AUTOSAR XML (schema 4-0-3)
package /ComponentTypes
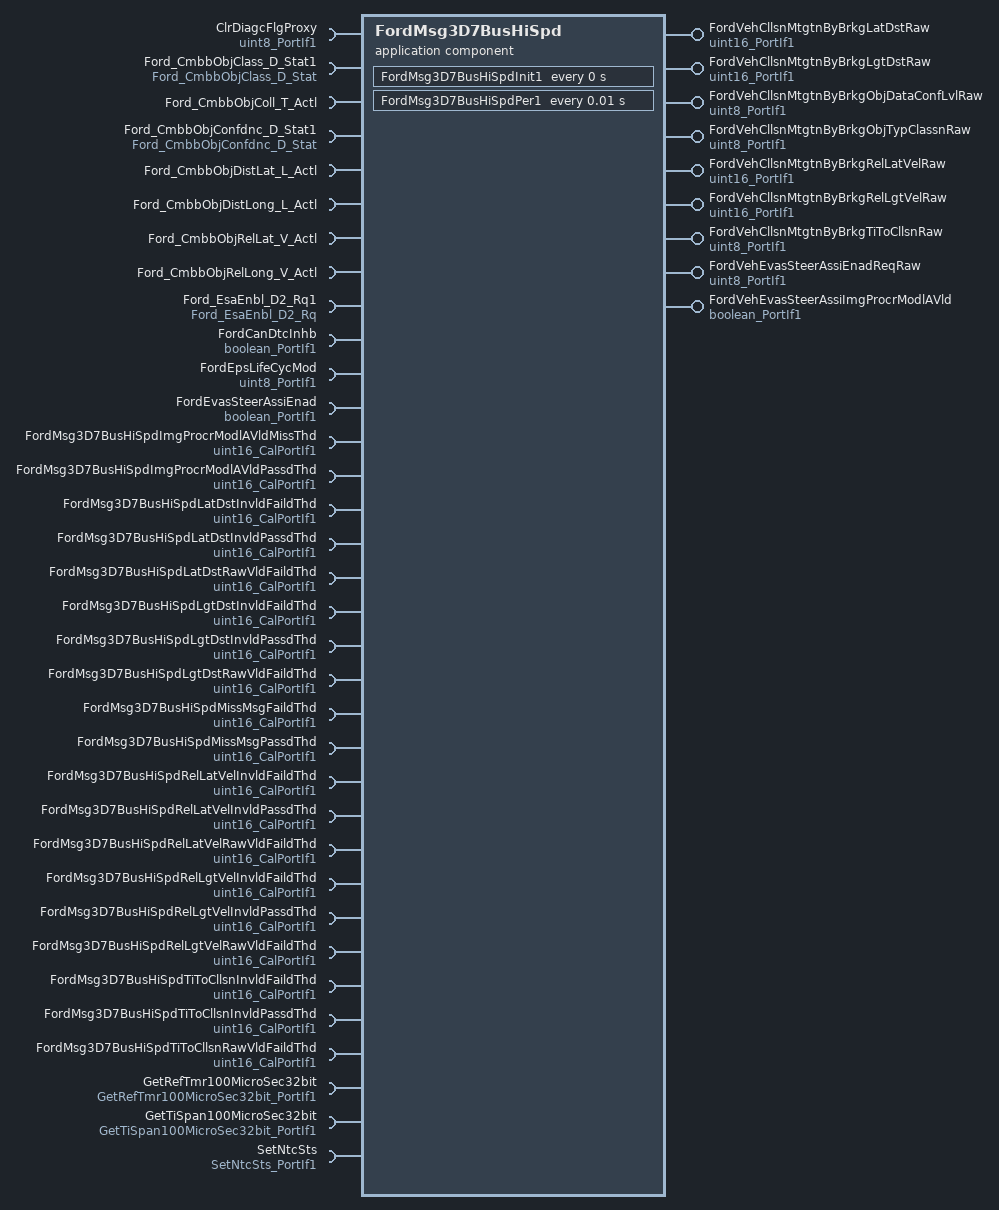
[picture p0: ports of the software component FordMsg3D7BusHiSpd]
  application sw component type FordMsg3D7BusHiSpd
    9 x provide port:
      FordVehCllsnMtgtnByBrkgLatDstRaw: nonqueued-sender-com-spec{data-element=Val, init-value=510}, provided-interface=uint16_PortIf1
      FordVehCllsnMtgtnByBrkgLgtDstRaw: nonqueued-sender-com-spec{data-element=Val, init-value=1022}, provided-interface=uint16_PortIf1
      FordVehCllsnMtgtnByBrkgObjDataConfLvlRaw: nonqueued-sender-com-spec{data-element=Val, init-value=0}, provided-interface=uint8_PortIf1
      FordVehCllsnMtgtnByBrkgObjTypClassnRaw: nonqueued-sender-com-spec{data-element=Val, init-value=0}, provided-interface=uint8_PortIf1
      FordVehCllsnMtgtnByBrkgRelLatVelRaw: nonqueued-sender-com-spec{data-element=Val, init-value=510}, provided-interface=uint16_PortIf1
      FordVehCllsnMtgtnByBrkgRelLgtVelRaw: nonqueued-sender-com-spec{data-element=Val, init-value=1022}, provided-interface=uint16_PortIf1
      FordVehCllsnMtgtnByBrkgTiToCllsnRaw: nonqueued-sender-com-spec{data-element=Val, init-value=126}, provided-interface=uint8_PortIf1
      FordVehEvasSteerAssiEnadReqRaw: nonqueued-sender-com-spec{data-element=Val, init-value=0}, provided-interface=uint8_PortIf1
      FordVehEvasSteerAssiImgProcrModlAVld: nonqueued-sender-com-spec{data-element=Logl, init-value=0}, provided-interface=boolean_PortIf1
    34 x require port:
      ClrDiagcFlgProxy: nonqueued-receiver-com-spec{data-element=Val, filter=data-filter-type=ALWAYS, init-value=0}, required-interface=uint8_PortIf1
      Ford_CmbbObjClass_D_Stat1: nonqueued-receiver-com-spec{data-element=Ford_CmbbObjClass_D_Stat, filter=data-filter-type=ALWAYS, init-value=0}, required-interface=Ford_CmbbObjClass_D_Stat
      Ford_CmbbObjColl_T_Actl: nonqueued-receiver-com-spec{data-element=Ford_CmbbObjColl_T_Actl, filter=data-filter-type=ALWAYS, init-value=126}, required-interface=Ford_CmbbObjColl_T_Actl
      Ford_CmbbObjConfdnc_D_Stat1: nonqueued-receiver-com-spec{data-element=Ford_CmbbObjConfdnc_D_Stat, filter=data-filter-type=ALWAYS, init-value=0}, required-interface=Ford_CmbbObjConfdnc_D_Stat
      Ford_CmbbObjDistLat_L_Actl: nonqueued-receiver-com-spec{data-element=Ford_CmbbObjDistLat_L_Actl, filter=data-filter-type=ALWAYS, init-value=510}, required-interface=Ford_CmbbObjDistLat_L_Actl
      Ford_CmbbObjDistLong_L_Actl: nonqueued-receiver-com-spec{data-element=Ford_CmbbObjDistLong_L_Actl, filter=data-filter-type=ALWAYS, init-value=1022}, required-interface=Ford_CmbbObjDistLong_L_Actl
      Ford_CmbbObjRelLat_V_Actl: nonqueued-receiver-com-spec{data-element=Ford_CmbbObjRelLat_V_Actl, filter=data-filter-type=ALWAYS, init-value=510}, required-interface=Ford_CmbbObjRelLat_V_Actl
      Ford_CmbbObjRelLong_V_Actl: nonqueued-receiver-com-spec{data-element=Ford_CmbbObjRelLong_V_Actl, filter=data-filter-type=ALWAYS, init-value=1022}, required-interface=Ford_CmbbObjRelLong_V_Actl
      Ford_EsaEnbl_D2_Rq1: nonqueued-receiver-com-spec{data-element=Ford_EsaEnbl_D2_Rq, filter=data-filter-type=ALWAYS, init-value=0}, required-interface=Ford_EsaEnbl_D2_Rq
      FordCanDtcInhb: nonqueued-receiver-com-spec{data-element=Logl, filter=data-filter-type=ALWAYS, init-value=1}, required-interface=boolean_PortIf1
      FordEpsLifeCycMod: nonqueued-receiver-com-spec{data-element=Val, filter=data-filter-type=ALWAYS, init-value=0}, required-interface=uint8_PortIf1
      FordEvasSteerAssiEnad: nonqueued-receiver-com-spec{data-element=Logl, filter=data-filter-type=ALWAYS, init-value=0}, required-interface=boolean_PortIf1
      FordMsg3D7BusHiSpdImgProcrModlAVldMissThd: parameter-require-com-spec{init-value=500, parameter=Val}, required-interface=uint16_CalPortIf1
      FordMsg3D7BusHiSpdImgProcrModlAVldPassdThd: parameter-require-com-spec{init-value=5000, parameter=Val}, required-interface=uint16_CalPortIf1
      FordMsg3D7BusHiSpdLatDstInvldFaildThd: parameter-require-com-spec{init-value=0, parameter=Val}, required-interface=uint16_CalPortIf1
      FordMsg3D7BusHiSpdLatDstInvldPassdThd: parameter-require-com-spec{init-value=0, parameter=Val}, required-interface=uint16_CalPortIf1
      FordMsg3D7BusHiSpdLatDstRawVldFaildThd: parameter-require-com-spec{init-value=0, parameter=Val}, required-interface=uint16_CalPortIf1
      FordMsg3D7BusHiSpdLgtDstInvldFaildThd: parameter-require-com-spec{init-value=0, parameter=Val}, required-interface=uint16_CalPortIf1
      FordMsg3D7BusHiSpdLgtDstInvldPassdThd: parameter-require-com-spec{init-value=0, parameter=Val}, required-interface=uint16_CalPortIf1
      FordMsg3D7BusHiSpdLgtDstRawVldFaildThd: parameter-require-com-spec{init-value=0, parameter=Val}, required-interface=uint16_CalPortIf1
      FordMsg3D7BusHiSpdMissMsgFaildThd: parameter-require-com-spec{init-value=500, parameter=Val}, required-interface=uint16_CalPortIf1
      FordMsg3D7BusHiSpdMissMsgPassdThd: parameter-require-com-spec{init-value=0, parameter=Val}, required-interface=uint16_CalPortIf1
      FordMsg3D7BusHiSpdRelLatVelInvldFaildThd: parameter-require-com-spec{init-value=0, parameter=Val}, required-interface=uint16_CalPortIf1
      FordMsg3D7BusHiSpdRelLatVelInvldPassdThd: parameter-require-com-spec{init-value=0, parameter=Val}, required-interface=uint16_CalPortIf1
      FordMsg3D7BusHiSpdRelLatVelRawVldFaildThd: parameter-require-com-spec{init-value=0, parameter=Val}, required-interface=uint16_CalPortIf1
      FordMsg3D7BusHiSpdRelLgtVelInvldFaildThd: parameter-require-com-spec{init-value=0, parameter=Val}, required-interface=uint16_CalPortIf1
      FordMsg3D7BusHiSpdRelLgtVelInvldPassdThd: parameter-require-com-spec{init-value=0, parameter=Val}, required-interface=uint16_CalPortIf1
      FordMsg3D7BusHiSpdRelLgtVelRawVldFaildThd: parameter-require-com-spec{init-value=0, parameter=Val}, required-interface=uint16_CalPortIf1
      FordMsg3D7BusHiSpdTiToCllsnInvldFaildThd: parameter-require-com-spec{init-value=0, parameter=Val}, required-interface=uint16_CalPortIf1
      FordMsg3D7BusHiSpdTiToCllsnInvldPassdThd: parameter-require-com-spec{init-value=0, parameter=Val}, required-interface=uint16_CalPortIf1
      FordMsg3D7BusHiSpdTiToCllsnRawVldFaildThd: parameter-require-com-spec{init-value=0, parameter=Val}, required-interface=uint16_CalPortIf1
      GetRefTmr100MicroSec32bit: client-com-spec=Oper, required-interface=GetRefTmr100MicroSec32bit_PortIf1
      GetTiSpan100MicroSec32bit: client-com-spec=Oper, required-interface=GetTiSpan100MicroSec32bit_PortIf1
      SetNtcSts: client-com-spec=Oper, required-interface=SetNtcSts_PortIf1
    behavior FordMsg3D7BusHiSpd_InternalBehavior
      ar-typed-per-instance-memorys:
        31 x data, all with sw-calibration-access=READ-ONLY:
          ClrDiagcFlgProxyPrev: type=uint8
          EvasSteerAssiImgProcrModlAVldPassdRefTi: type=uint32
          FirstTranVldFlg: type=boolean
          FordVehCllsnMtgtnByBrkgLatDstInvldFaildRefTi: type=uint32
          FordVehCllsnMtgtnByBrkgLatDstInvldPassdRefTi: type=uint32
          FordVehCllsnMtgtnByBrkgLatDstRawPrev: type=uint16
          FordVehCllsnMtgtnByBrkgLgtDstInvldFaildRefTi: type=uint32
          FordVehCllsnMtgtnByBrkgLgtDstInvldPassdRefTi: type=uint32
          FordVehCllsnMtgtnByBrkgLgtDstRawPrev: type=uint16
          FordVehCllsnMtgtnByBrkgObjDataConfLvlRawPrev: type=uint8
          FordVehCllsnMtgtnByBrkgObjTypClassnRawPrev: type=uint8
          FordVehCllsnMtgtnByBrkgRelLatVelInvldFaildRefTi: type=uint32
          FordVehCllsnMtgtnByBrkgRelLatVelInvldPassdRefTi: type=uint32
          FordVehCllsnMtgtnByBrkgRelLatVelRawPrev: type=uint16
          FordVehCllsnMtgtnByBrkgRelLgtVelInvldFaildRefTi: type=uint32
          FordVehCllsnMtgtnByBrkgRelLgtVelInvldPassdRefTi: type=uint32
          FordVehCllsnMtgtnByBrkgRelLgtVelRawPrev: type=uint16
          FordVehCllsnMtgtnByBrkgTiToCllsnInvldFaildRefTi: type=uint32
          FordVehCllsnMtgtnByBrkgTiToCllsnInvldPassdRefTi: type=uint32
          FordVehCllsnMtgtnByBrkgTiToCllsnRawPrev: type=uint8
          FordVehEvasSteerAssiEnadReqRawPrev: type=uint8
          FordVehEvasSteerAssiImgProcrModlAVldPrev: type=boolean
          FordVehMsg3D7Miss: type=boolean
          ImgProcrModlAVldMissRefTi: type=uint32
          LatDstRawVldFaildRefTi: type=uint32
          LgtDstRawVldFaildRefTi: type=uint32
          MissMsgFaildRefTi: type=uint32
          MissMsgPassdRefTi: type=uint32
          RelLatVelRawVldFaildRefTi: type=uint32
          RelLgtVelRawVldFaildRefTi: type=uint32
          TiToCllsnRawVldFaildRefTi: type=uint32
      timing event FordMsg3D7BusHiSpd_InitEvent: start-on-event=FordMsg3D7BusHiSpdInit1, period=0
      timing event TMT_FordMsg3D7BusHiSpdPer1: start-on-event=FordMsg3D7BusHiSpdPer1, period=0.01
      port-api-options:
        enable-take-address=false, indirect-api=false, port=ClrDiagcFlgProxy
        enable-take-address=false, indirect-api=false, port=Ford_CmbbObjClass_D_Stat1
        enable-take-address=false, indirect-api=false, port=Ford_CmbbObjColl_T_Actl
        enable-take-address=false, indirect-api=false, port=Ford_CmbbObjConfdnc_D_Stat1
        enable-take-address=false, indirect-api=false, port=Ford_CmbbObjDistLat_L_Actl
        enable-take-address=false, indirect-api=false, port=Ford_CmbbObjDistLong_L_Actl
        enable-take-address=false, indirect-api=false, port=Ford_CmbbObjRelLat_V_Actl
        enable-take-address=false, indirect-api=false, port=Ford_CmbbObjRelLong_V_Actl
        enable-take-address=false, indirect-api=false, port=Ford_EsaEnbl_D2_Rq1
        enable-take-address=false, indirect-api=false, port=FordCanDtcInhb
        enable-take-address=false, indirect-api=false, port=FordEpsLifeCycMod
        enable-take-address=false, indirect-api=false, port=FordEvasSteerAssiEnad
        enable-take-address=false, indirect-api=false, port=FordMsg3D7BusHiSpdImgProcrModlAVldMissThd
        enable-take-address=false, indirect-api=false, port=FordMsg3D7BusHiSpdImgProcrModlAVldPassdThd
        enable-take-address=false, indirect-api=false, port=FordMsg3D7BusHiSpdLatDstInvldFaildThd
        enable-take-address=false, indirect-api=false, port=FordMsg3D7BusHiSpdLatDstInvldPassdThd
        enable-take-address=false, indirect-api=false, port=FordMsg3D7BusHiSpdLatDstRawVldFaildThd
        enable-take-address=false, indirect-api=false, port=FordMsg3D7BusHiSpdLgtDstInvldFaildThd
        enable-take-address=false, indirect-api=false, port=FordMsg3D7BusHiSpdLgtDstInvldPassdThd
        enable-take-address=false, indirect-api=false, port=FordMsg3D7BusHiSpdLgtDstRawVldFaildThd
        enable-take-address=false, indirect-api=false, port=FordMsg3D7BusHiSpdMissMsgFaildThd
        enable-take-address=false, indirect-api=false, port=FordMsg3D7BusHiSpdMissMsgPassdThd
        enable-take-address=false, indirect-api=false, port=FordMsg3D7BusHiSpdRelLatVelInvldFaildThd
        enable-take-address=false, indirect-api=false, port=FordMsg3D7BusHiSpdRelLatVelInvldPassdThd
        enable-take-address=false, indirect-api=false, port=FordMsg3D7BusHiSpdRelLatVelRawVldFaildThd
        enable-take-address=false, indirect-api=false, port=FordMsg3D7BusHiSpdRelLgtVelInvldFaildThd
        enable-take-address=false, indirect-api=false, port=FordMsg3D7BusHiSpdRelLgtVelInvldPassdThd
        enable-take-address=false, indirect-api=false, port=FordMsg3D7BusHiSpdRelLgtVelRawVldFaildThd
        enable-take-address=false, indirect-api=false, port=FordMsg3D7BusHiSpdTiToCllsnInvldFaildThd
        enable-take-address=false, indirect-api=false, port=FordMsg3D7BusHiSpdTiToCllsnInvldPassdThd
        enable-take-address=false, indirect-api=false, port=FordMsg3D7BusHiSpdTiToCllsnRawVldFaildThd
        enable-take-address=false, indirect-api=false, port=FordVehCllsnMtgtnByBrkgLatDstRaw
        enable-take-address=false, indirect-api=false, port=FordVehCllsnMtgtnByBrkgLgtDstRaw
        enable-take-address=false, indirect-api=false, port=FordVehCllsnMtgtnByBrkgObjDataConfLvlRaw
        enable-take-address=false, indirect-api=false, port=FordVehCllsnMtgtnByBrkgObjTypClassnRaw
        enable-take-address=false, indirect-api=false, port=FordVehCllsnMtgtnByBrkgRelLatVelRaw
        enable-take-address=false, indirect-api=false, port=FordVehCllsnMtgtnByBrkgRelLgtVelRaw
        enable-take-address=false, indirect-api=false, port=FordVehCllsnMtgtnByBrkgTiToCllsnRaw
        enable-take-address=false, indirect-api=false, port=FordVehEvasSteerAssiEnadReqRaw
        enable-take-address=false, indirect-api=false, port=FordVehEvasSteerAssiImgProcrModlAVld
        enable-take-address=false, indirect-api=false, port=GetRefTmr100MicroSec32bit
        enable-take-address=false, indirect-api=false, port=GetTiSpan100MicroSec32bit
        enable-take-address=false, indirect-api=false, port=SetNtcSts
      runnable FordMsg3D7BusHiSpdInit1
        sync call SC_GetRefTmr100MicroSec32bit_Oper: operation=GetRefTmr100MicroSec32bit.Oper, timeout=0
      runnable FordMsg3D7BusHiSpdPer1
        data-receive-point-by-arguments:
          12 x access:
            REC_ClrDiagcFlgProxy_Val: accessed-variable=ClrDiagcFlgProxy.Val
            REC_Ford_CmbbObjClass_D_Stat1_Ford_CmbbObjClass_D_Stat: accessed-variable=Ford_CmbbObjClass_D_Stat1.Ford_CmbbObjClass_D_Stat
            REC_Ford_CmbbObjColl_T_Actl_Ford_CmbbObjColl_T_Actl: accessed-variable=Ford_CmbbObjColl_T_Actl.Ford_CmbbObjColl_T_Actl
            REC_Ford_CmbbObjConfdnc_D_Stat1_Ford_CmbbObjConfdnc_D_Stat: accessed-variable=Ford_CmbbObjConfdnc_D_Stat1.Ford_CmbbObjConfdnc_D_Stat
            REC_Ford_CmbbObjDistLat_L_Actl_Ford_CmbbObjDistLat_L_Actl: accessed-variable=Ford_CmbbObjDistLat_L_Actl.Ford_CmbbObjDistLat_L_Actl
            REC_Ford_CmbbObjDistLong_L_Actl_Ford_CmbbObjDistLong_L_Actl: accessed-variable=Ford_CmbbObjDistLong_L_Actl.Ford_CmbbObjDistLong_L_Actl
            REC_Ford_CmbbObjRelLat_V_Actl_Ford_CmbbObjRelLat_V_Actl: accessed-variable=Ford_CmbbObjRelLat_V_Actl.Ford_CmbbObjRelLat_V_Actl
            REC_Ford_CmbbObjRelLong_V_Actl_Ford_CmbbObjRelLong_V_Actl: accessed-variable=Ford_CmbbObjRelLong_V_Actl.Ford_CmbbObjRelLong_V_Actl
            REC_Ford_EsaEnbl_D2_Rq1_Ford_EsaEnbl_D2_Rq: accessed-variable=Ford_EsaEnbl_D2_Rq1.Ford_EsaEnbl_D2_Rq
            REC_FordCanDtcInhb_Logl: accessed-variable=FordCanDtcInhb.Logl
            REC_FordEpsLifeCycMod_Val: accessed-variable=FordEpsLifeCycMod.Val
            REC_FordEvasSteerAssiEnad_Logl: accessed-variable=FordEvasSteerAssiEnad.Logl
        data-send-points:
          9 x access:
            SEND_FordVehCllsnMtgtnByBrkgLatDstRaw_Val: accessed-variable=FordVehCllsnMtgtnByBrkgLatDstRaw.Val
            SEND_FordVehCllsnMtgtnByBrkgLgtDstRaw_Val: accessed-variable=FordVehCllsnMtgtnByBrkgLgtDstRaw.Val
            SEND_FordVehCllsnMtgtnByBrkgObjDataConfLvlRaw_Val: accessed-variable=FordVehCllsnMtgtnByBrkgObjDataConfLvlRaw.Val
            SEND_FordVehCllsnMtgtnByBrkgObjTypClassnRaw_Val: accessed-variable=FordVehCllsnMtgtnByBrkgObjTypClassnRaw.Val
            SEND_FordVehCllsnMtgtnByBrkgRelLatVelRaw_Val: accessed-variable=FordVehCllsnMtgtnByBrkgRelLatVelRaw.Val
            SEND_FordVehCllsnMtgtnByBrkgRelLgtVelRaw_Val: accessed-variable=FordVehCllsnMtgtnByBrkgRelLgtVelRaw.Val
            SEND_FordVehCllsnMtgtnByBrkgTiToCllsnRaw_Val: accessed-variable=FordVehCllsnMtgtnByBrkgTiToCllsnRaw.Val
            SEND_FordVehEvasSteerAssiEnadReqRaw_Val: accessed-variable=FordVehEvasSteerAssiEnadReqRaw.Val
            SEND_FordVehEvasSteerAssiImgProcrModlAVld_Logl: accessed-variable=FordVehEvasSteerAssiImgProcrModlAVld.Logl
        sync call SC_GetRefTmr100MicroSec32bit_Oper: operation=GetRefTmr100MicroSec32bit.Oper, timeout=0
        sync call SC_GetTiSpan100MicroSec32bit_Oper: operation=GetTiSpan100MicroSec32bit.Oper, timeout=0
        sync call SC_SetNtcSts_Oper: operation=SetNtcSts.Oper, timeout=0
  swc implementation FordMsg3D7BusHiSpd_Implementation: behavior=FordMsg3D7BusHiSpd_InternalBehavior
    code-descriptors:
      code Default: artifact-descriptors=autosar-engineering-object={short-label=Default, category=SWSRC}
